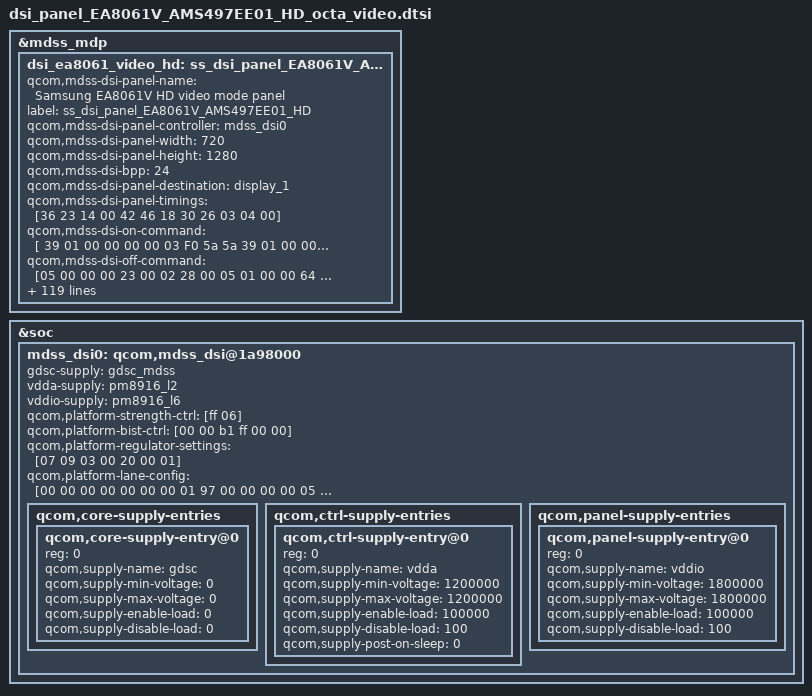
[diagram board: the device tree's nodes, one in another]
/* Copyright (c) 2013-2014, The Linux Foundation. All rights reserved.
 *
 * This program is free software; you can redistribute it and/or modify
 * it under the terms of the GNU General Public License version 2 and
 * only version 2 as published by the Free Software Foundation.
 *
 * This program is distributed in the hope that it will be useful,
 * but WITHOUT ANY WARRANTY; without even the implied warranty of
 * MERCHANTABILITY or FITNESS FOR A PARTICULAR PURPOSE.  See the
 * GNU General Public License for more details.
 */

/*---------------------------------------------------------------------------
 * This file is autogenerated file using gcdb parser. Please do not edit it.
 * Update input XML file to add a new entry or update variable in this file
 * VERSION = "1.0"
 *--------------------------------------------------------------------------- */
&mdss_mdp {
	dsi_ea8061_video_hd: ss_dsi_panel_EA8061V_AMS497EE01_HD {
		qcom,mdss-dsi-panel-name = "Samsung EA8061V HD video mode panel";
		label = "ss_dsi_panel_EA8061V_AMS497EE01_HD";
		qcom,mdss-dsi-panel-controller = <&mdss_dsi0>;
		qcom,mdss-dsi-panel-width = <720>;
		qcom,mdss-dsi-panel-height = <1280>;
		qcom,mdss-dsi-bpp = <24>;

		qcom,mdss-dsi-panel-destination = "display_1";
		qcom,mdss-dsi-panel-timings = [36 23 14 00 42 46 18 30 26 03 04 00];

		qcom,mdss-dsi-on-command = [
				39 01 00 00 00 00 03 F0 5a 5a
				39 01 00 00 00 00 03 F1 5a 5a

				/* common condition set */
				39 01 00 00 00 00 03 B8 19 10
				39 01 00 00 00 00 02 BA 57
				39 01 00 00 00 00 03 FC 5a 5a
				39 01 00 00 00 00 02 B0 0B
				39 01 00 00 00 00 03 D2 00 85
				39 01 00 00 00 00 02 CB 70
				39 01 00 00 00 00 03 FC a5 a5

				/* brightness control */
				39 01 00 00 00 00 22 CA
				    01 00 01 00 01 00
				    80 80 80 80 80 80
				    80 80 80 80 80 80
				    80 80 80 80 80 80
				    80 80 80 80 80 80
				    00 00 00
				39 01 00 00 00 00 05 B2 00 00 00 0a
				39 01 00 00 00 00 03 B6 5c 8a
				39 01 00 00 00 00 02 F7 01

				05 01 00 00 78 00 02 11 00
				39 01 00 00 00 00 03 F1 A5 A5
					];

		qcom,mdss-dsi-off-command = [05 00 00 00 23 00 02 28 00
				 05 01 00 00 64 00 02 10 00];

		qcom,mdss-dsi-panel-type = "dsi_video_mode";

		qcom,mdss-dsi-panel-framerate = <60>;
		qcom,mdss-dsi-virtual-channel-id = <0>;
		qcom,mdss-dsi-stream = <0>;
		qcom,cont-splash-enabled;
		qcom,mdss-dsi-force-clk-lane-hs;

		qcom,mdss-dsi-h-front-porch = <80>;
		qcom,mdss-dsi-h-back-porch = <128>;
		qcom,mdss-dsi-h-pulse-width = <96>;
		qcom,mdss-dsi-h-sync-skew = <0>;
		qcom,mdss-dsi-v-back-porch = <8>;
		qcom,mdss-dsi-v-front-porch = <14>;
		qcom,mdss-dsi-v-pulse-width = <2>;
		qcom,mdss-dsi-h-left-border = <0>;
		qcom,mdss-dsi-h-right-border = <0>;
		qcom,mdss-dsi-v-top-border = <0>;
		qcom,mdss-dsi-v-bottom-border = <0>;

		qcom,mdss-dsi-underflow-color = <0xff>;
		qcom,mdss-dsi-border-color = <0>;

		/* Dynamic FPS
		qcom,mdss-dsi-pan-enable-dynamic-fps= <1>;
		qcom,mdss-dsi-pan-fps-update = "dfps_immediate_porch_mode";*/


		qcom,mdss-dsi-gamma-update = [39 01 00 00 00 00 02 F7 01];
		qcom,mdss-dsi-on-command-state = "dsi_lp_mode";
		qcom,mdss-dsi-off-command-state = "dsi_hs_mode";
		qcom,mdss-dsi-h-sync-pulse = <0>;
		qcom,mdss-dsi-traffic-mode = "burst_mode";
		qcom,mdss-dsi-bllp-eof-power-mode;
		qcom,mdss-dsi-bllp-power-mode;
		qcom,mdss-dsi-lane-0-state;
		qcom,mdss-dsi-lane-1-state;
		qcom,mdss-dsi-lane-2-state;
		qcom,mdss-dsi-lane-3-state;

		qcom,mdss-dsi-t-clk-post = <0x04>;
		qcom,mdss-dsi-t-clk-pre = <0x1b>;
		qcom,mdss-dsi-bl-min-level = <1>;
		qcom,mdss-dsi-bl-max-level = <255>;
		qcom,mdss-dsi-dma-trigger = "trigger_sw";
		qcom,mdss-dsi-mdp-trigger = "none";

		qcom,mdss-dsi-bl-pmic-control-type = "bl_ctrl_dcs";
		qcom,mdss-dsi-reset-sequence = <1 20>, <0 1>, <1 20>;
		qcom,mdss-pan-physical-width-dimension = <62>;
		qcom,mdss-pan-physical-height-dimension = <110>;
		qcom,mdss-dsi-lp11-init;
		qcom,mdss-dsi-init-delay-us = <2000>;
		qcom,mdss-power-off-delay-us = <12000>;


/*
 * ************************************************************************************************************************************
 *
 *
 *			Below  parameters are samsung dependent thigs
 *
 *
 * ************************************************************************************************************************************
 */

		samsung,packet_size_tx_cmds_revA = [
			37 01 00 00 00 00 02 07 00
		];

		/*
		 * First parameters can be changed
		 * by function of samsung_nv_read()
		 * because of that means offset of
		 * read position
		 */
		samsung,reg_read_pos_tx_cmds_revA = [
			15 01 00 00 00 00 02 B0 00
		];

		samsung,display_on_tx_cmds_revA = [05 01 00 00 32 00 02 29 00];
		samsung,display_off_tx_cmds_revA = [05 01 00 00 32 00 02 28 00];

		samsung,level1_key_enable_tx_cmds_revA = [
			29 01 00 00 00 00 03 F0 5A 5A
		];
		samsung,level1_key_disable_tx_cmds_revA = [
			29 01 00 00 00 00 03 F0 A5 A5
		];
		samsung,level2_key_enable_tx_cmds_revA = [
			29 01 00 00 00 00 03 F0 5A 5A
			29 01 00 00 00 00 03 F1 5A 5A
			29 01 00 00 00 00 03 FC 5A 5A
		];
		samsung,level2_key_disable_tx_cmds_revA = [
			29 01 00 00 00 00 03 F0 A5 A5
			29 01 00 00 00 00 03 F1 A5 A5
			29 01 00 00 00 00 03 FC A5 A5
		];


		/*
		 * ************************************************************************************************************************
		 *	 06 01 00 00 00 00 01 c8 07 21
		 *	READ 0xC8 SIZE 0x07 OFFSET 0x21
		 * ************************************************************************************************************************
		 */
		samsung,smart_dimming_mtp_rx_cmds_revA = [ 06 01 00 00 00 00 01 c8 21 00];
		/* the last byte in all read commands will represent READ LENGH */
		samsung,manufacture_id0_rx_cmds_revA = [ 06 01 00 00 00 00 01 da 01 00];
		samsung,manufacture_id1_rx_cmds_revA = [ 06 01 00 00 00 00 01 db 01 00];
		samsung,manufacture_id2_rx_cmds_revA = [ 06 01 00 00 00 00 01 dc 01 00];

		samsung,manufacture_date_rx_cmds_revA = [ 06 01 00 00 00 00 01 c8 02 28];	/* read C8 41~42th , 40=0x28*/
		samsung,ddi_id_rx_cmds_revA = [ 06 01 00 00 00 00 01 d6 05 00];	/* read D6 1~5th */
		samsung,mtp_read_sysfs_rx_cmds_revA = [ 06 01 00 00 00 00 01 01 01 01];

		samsung,hbm_rx_cmds_revA = [ 06 01 00 00 00 00 01 c8 07 21];	/* read C8 34~40th , 33=0x21*/
		samsung,hbm2_rx_cmds_revA = [ 06 01 00 00 00 00 01 c8 0F 48];	/* read C8 73~87th , 72=0x48*/

		samsung,elvss_rx_cmds_revA = [ 06 01 00 00 00 00 01 b6 01 14];	/* read C6 21th , 20=0x14*/
		samsung,mdnie_read_rx_cmds_revA	= [ 06 01 00 00 00 00 01 A1 04 00];

		samsung,ldi_debug0_rx_cmds_revA = [06 01 00 00 00 00 01 0A 01 00];
		samsung,ldi_debug1_rx_cmds_revA = [06 01 00 00 00 00 01 0E 01 00];
		samsung,ldi_debug2_rx_cmds_revA = [06 01 00 00 00 00 01 EA 08 00];





		/*
		 * ************************************************************************************************************************
		 *	 COMMON CMD LIST
		 * ************************************************************************************************************************
		*/

		samsung,gamma_tx_cmds_revA = [
			29 01 00 00 00 00 22            /* Brightness Condition Set - Gamma 2.2 Setting*/
				CA 01 00 01 00 01 00 80
				80 80 80 80 80 80 80 80
				80 80 80 80 80 80 80 80
				80 80 80 80 80 80 80 00
				00 00
			29 01 00 00 00 00 02 F7 01	/* Gamma, LTPS(AID) update */
			];

		samsung,hbm_gamma_tx_cmds_revA = [
				29 01 00 00 00 00 22	/* Brightness Condition Set for HBM - Gamma 2.2 Setting*/
				CA 01 00 01 00 01 00 80
				80 80 80 80 80 80 80 80
				80 80 80 80 80 80 80 80
				80 80 80 80 80 80 80 00
				00 00
			];

		samsung,hbm_etc_tx_cmds_revA = [
			29 01 00 00 00 00 05 B2 00 0E 00 0E	/* AID 0% */
			29 01 00 00 00 00 16 B6
				88 04 00 00 00
				00 00 03 55 54
				20 00 0A AA AF
				0F 02 11 11 10
				00			/* HBM ELVSS Setting */
			/*29 01 00 00 00 00 07 B5 03 99 27 1F 45 0A*/	/* ACL control */
			29 01 00 00 00 00 02 55 02	/* RE(low) & ACL */
			29 01 00 00 00 00 02 B5 29	/* 32 frame Averaging (0x51) */
			29 01 00 00 00 00 02 00 00
			29 01 00 00 00 00 02 F7 01	/* Gamma, LTPS(AID) update */
			29 01 00 00 00 00 02 00 00
			29 01 00 00 00 00 02 F7 00
		];



		/*
		* ************************************************************************************************************************
		* AID command list and mappings
		* ************************************************************************************************************************
		*/

		samsung,aid_tx_cmds_revA = [
					39 00 00 00 00 00 05	B2 00 00 04 E4	/* 0 samsung_brightness_aor_95p7 */
					39 00 00 00 00 00 05	B2 00 00 04 DA	/* 1 samsung_brightness_aor_94p25 */
					39 00 00 00 00 00 05	B2 00 00 04 D0	/* 2 samsung_brightness_aor_93p33 */
					39 00 00 00 00 00 05	B2 00 00 04 C4	/* 3 samsung_brightness_aor_92p41 */
					39 00 00 00 00 00 05	B2 00 00 04 B8	/* 4 samsung_brightness_aor_91p41 */
					39 00 00 00 00 00 05	B2 00 00 04 AE	/* 5 samsung_brightness_aor_90p49 */
					39 00 00 00 00 00 05	B2 00 00 04 A4	/* 6 samsung_brightness_aor_89p65 */
					39 00 00 00 00 00 05	B2 00 00 04 98	/* 7 samsung_brightness_aor_88p73 */
					39 00 00 00 00 00 05	B2 00 00 04 8C	/* 8 samsung_brightness_aor_87p88 */
					39 00 00 00 00 00 05	B2 00 00 04 80	/* 9 samsung_brightness_aor_87p04 */
					39 00 00 00 00 00 05	B2 00 00 04 74	/* 10 samsung_brightness_aor_85p89 */
					39 00 00 00 00 00 05	B2 00 00 04 68	/* 11 samsung_brightness_aor_84p97 */
					39 00 00 00 00 00 05	B2 00 00 04 5C	/* 12 samsung_brightness_aor_84p05 */
					39 00 00 00 00 00 05	B2 00 00 04 44	/* 13 samsung_brightness_aor_82p21 */
					39 00 00 00 00 00 05	B2 00 00 04 38	/* 14 samsung_brightness_aor_81p21 */
					39 00 00 00 00 00 05	B2 00 00 04 25	/* 15 samsung_brightness_aor_80p83 */
					39 00 00 00 00 00 05	B2 00 00 04 18	/* 16 samsung_brightness_aor_80p29 */
					39 00 00 00 00 00 05	B2 00 00 04 01	/* 17 samsung_brightness_aor_77p61 */
					39 00 00 00 00 00 05	B2 00 00 03 F5	/* 18 samsung_brightness_aor_76p69 */
					39 00 00 00 00 00 05	B2 00 00 03 DB	/* 19 samsung_brightness_aor_74p92 */
					39 00 00 00 00 00 05	B2 00 00 03 C5	/* 20 samsung_brightness_aor_73p08 */
					39 00 00 00 00 00 05	B2 00 00 03 B7	/* 21 samsung_brightness_aor_72p09 */
					39 00 00 00 00 00 05	B2 00 00 03 9E	/* 22 samsung_brightness_aor_70p17 */
					39 00 00 00 00 00 05	B2 00 00 03 88	/* 23 samsung_brightness_aor_68p25 */
					39 00 00 00 00 00 05	B2 00 00 03 64	/* 24 samsung_brightness_aor_65p41 */
					39 00 00 00 00 00 05	B2 00 00 03 4B	/* 25 samsung_brightness_aor_63p50 */
					39 00 00 00 00 00 05	B2 00 00 03 32	/* 26 samsung_brightness_aor_61p58 */
					39 00 00 00 00 00 05	B2 00 00 03 0D	/* 27 samsung_brightness_aor_58p82 */
					39 00 00 00 00 00 05	B2 00 00 02 E7	/* 28 samsung_brightness_aor_53p22 */
					39 00 00 00 00 00 05	B2 00 00 02 C2	/* 29 samsung_brightness_aor_50p38 */
					39 00 00 00 00 00 05	B2 00 00 02 9D	/* 30 samsung_brightness_aor_47p62 */
					39 00 00 00 00 00 05	B2 00 00 02 79	/* 31 samsung_brightness_aor_43p87 */
					39 00 00 00 00 00 05	B2 00 00 02 45	/* 32 samsung_brightness_aor_40p11 */
					39 00 00 00 00 00 05	B2 00 00 02 13	/* 33 samsung_brightness_aor_39p95 */
					39 00 00 00 00 00 05	B2 00 00 01 E7	/* 34 samsung_brightness_aor_37p35 */
					39 00 00 00 00 00 05	B2 00 00 01 AE	/* 35 samsung_brightness_aor_32p29 */
					39 00 00 00 00 00 05	B2 00 00 01 76	/* 36 samsung_brightness_aor_27p99 */
					39 00 00 00 00 00 05	B2 00 00 01 39	/* 37 samsung_brightness_aor_22p70 */
					39 00 00 00 00 00 05	B2 00 00 00 F8	/* 38 samsung_brightness_aor_17p33 */
					39 00 00 00 00 00 05	B2 00 00 00 B4	/* 39 samsung_brightness_aor_11p66 */
					39 00 00 00 00 00 05	B2 00 00 00 63	/* 40 samsung_brightness_aor_11p66 */
					39 00 00 00 00 00 05	B2 00 00 00 0A	/* 41 samsung_brightness_aor_5p37 */
			];


		samsung,aid_map_table_revA = <
				5	0		6	1		7	2		8	3		9	4
				10	5		11	6		12	7		13	8		14	9
				15	10		16	11		17	12		19	13		20	14
				21	15		22	16		24	17		25	18		27	19
				29	20		30	21		32	22		34	23		37	24
				39	25		41	26		44	27		47	28		50	29
				53	30		56	31		60	32		64	33		68	34
				72	34		77	34		82	34		87	34		93	34
				98	34		105	34		111	34		119	34		126	34
				134	34		143	34		152	34		162	34		172	35
				183	36		195	37		207	38		220	39		234	40
				249	41		265	41		282	41		300	41		316	41
				333	41		350	41		360	41
		>;

		/*
		* ************************************************************************************************************************
		* ACL command list and mappings
		* ************************************************************************************************************************
		*/
		samsung,acl_on_tx_cmds_revA = [
			29 01 00 00 00 00 02 B5 29	/* ACL ON - 50 (32Frame Averaging) */			
			29 01 00 00 00 00 02 55 02	/* ACL 15%(default) */
/*			29 01 00 00 00 00 02 F7 01*/
		];

		samsung,acl_off_tx_cmds_revA = [
			29 01 00 00 00 00 02 B5 21	/* ACL ON - 50 (32Frame Averaging) */
			29 01 00 00 00 00 02 55 00	/* ACL 15%(default) */
/*			29 01 00 00 00 00 02 F7 01*/
		];

		samsung,acl_percent_tx_cmds_revA = [
			29 01 00 00 00 00 02 55 00
			29 01 00 00 00 00 02 55 01	/* ACL 25% */
			29 01 00 00 00 00 02 55 02	/* default ACL 15% */
			29 01 00 00 00 00 02 55 40	/* ACL 50% */

		];



		samsung,acl_map_table_revA =  <
					5    2	6    2	7    2	8    2	9    2
					10   2	11   2	12   2	13   2	14   2
					15   2	16   2	17   2	19   2	20   2
					21   2	22   2	24   2	25   2	27   2
					29   2	30   2	32   2	34   2	37   2
					39   2	41   2	44   2	47   2	50   2
					53   2	56   2	60   2	64   2	68   2
					72   2	77   2	82   2	87   2	93   2
					98   2	105  2	111  2	119  2	126  2
					134  2	143  2	152  2	162  2	172  2
					183  2	195  2	207  2	220  2	234  2
					249  2	265  2	282  2	300  2	316  2
					333  2	350  2	360  2
		>;

		/*
		 * ************************************************************************************************************************
		 * ELVSS(ACL Off) command list and mappings
		 * ************************************************************************************************************************
		 */
		samsung,elvss_tx_cmds_revA = [
					39 00 00 00 00 00 03 b6 4c 8A /* 0    5~7 nit : 0x8A */
					39 00 00 00 00 00 03 b6 4c 8B /* 1    8 nit  : 0x8B */
					39 00 00 00 00 00 03 b6 4c 8C /* 2    9 nit  : 0x8C */
					39 00 00 00 00 00 03 b6 4c 8D /* 3    10 nit : 0x8D */
					39 00 00 00 00 00 03 b6 4c 8E /* 4    11 nit : 0x8E */
					39 00 00 00 00 00 03 b6 4c 8F /* 5    12 nit : 0x8F */
					39 00 00 00 00 00 03 b6 4c 90 /* 6    13 nit : 0x90 */
					39 00 00 00 00 00 03 b6 4c 91 /* 7    14 nit : 0x91 */
					39 00 00 00 00 00 03 b6 4c 92 /* 8    15 nit : 0x92 */
					39 00 00 00 00 00 03 b6 4c 93 /* 9    16 nit : 0x93 */
					39 00 00 00 00 00 03 b6 4c 94 /* 10   17 nit : 0x94 */
					39 00 00 00 00 00 03 b6 4c 95 /* 11   19 nit : 0x95 */
					39 00 00 00 00 00 03 b6 5c 96 /* 12   20 nit : 0x96 */
					39 00 00 00 00 00 03 b6 5c 9B /* 13   82 ~ 21 nit : 0x9B */
					39 00 00 00 00 00 03 b6 5c 9A /* 14   93 ~ 87 nit : 0x9A */
					39 00 00 00 00 00 03 b6 5c 99 /* 15   105 ~ 98 nit : 0x99 */
					39 00 00 00 00 00 03 b6 5c 98 /* 16   111 nit : 0x98 */
					39 00 00 00 00 00 03 b6 5c 97 /* 17   126 ~ 119 nit : 0x97 */
					39 00 00 00 00 00 03 b6 5c 96 /* 18   134 nit : 0x96 */
					39 00 00 00 00 00 03 b6 5c 95 /* 19   143 nit : 0x95 */
					39 00 00 00 00 00 03 b6 5c 94 /* 20   172 ~ 152 nit : 0x94 */
					39 00 00 00 00 00 03 b6 5c 93 /* 21   183 nit : 0x93 */
					39 00 00 00 00 00 03 b6 5c 92 /* 22   195 nit : 0x92 */
					39 00 00 00 00 00 03 b6 5c 91 /* 23   207 nit : 0x91 */
					39 00 00 00 00 00 03 b6 5c 90 /* 24   249 ~ 220 nit : 0x90 */
					39 00 00 00 00 00 03 b6 5c 8F /* 25   265 nit : 0x8F */
					39 00 00 00 00 00 03 b6 5c 8E /* 26   282 nit : 0x8E */
					39 00 00 00 00 00 03 b6 5c 8D /* 27   300 nit : 0x8D */
					39 00 00 00 00 00 03 b6 5c 8C /* 28   316 nit : 0x8C */
					39 00 00 00 00 00 03 b6 5c 8B /* 29   333 nit : 0x8B */
					39 00 00 00 00 00 03 b6 5c 8A /* 30   350 nit : 0x8A */
		];

		/*
		* ************************************************************************************************************************
		 * SMART ACL(ACL On) ELVSS command list and mappings
		* ************************************************************************************************************************
		*/
		samsung,smart_acl_elvss_tx_cmds_revA = [
					39 00 00 00 00 00 03 b6 4c 8A /* 0    5~7 nit : 0x8A */
					39 00 00 00 00 00 03 b6 4c 8B /* 1    8 nit : 0x8B */
					39 00 00 00 00 00 03 b6 4c 8C /* 2    9 nit : 0x8C */
					39 00 00 00 00 00 03 b6 4c 8D /* 3    10 nit : 0x8D */
					39 00 00 00 00 00 03 b6 4c 8E /* 4    11 nit : 0x8E */
					39 00 00 00 00 00 03 b6 4c 8F /* 5    12 nit : 0x8F */
					39 00 00 00 00 00 03 b6 4c 90 /* 6    13 nit : 0x90 */
					39 00 00 00 00 00 03 b6 4c 91 /* 7    14 nit : 0x91 */
					39 00 00 00 00 00 03 b6 4c 92 /* 8    15 nit : 0x92 */
					39 00 00 00 00 00 03 b6 4c 93 /* 9    16 nit : 0x93 */
					39 00 00 00 00 00 03 b6 4c 94 /* 10   17 nit : 0x94 */
					39 00 00 00 00 00 03 b6 4c 95 /* 11   19 nit : 0x95 */
					39 00 00 00 00 00 03 b6 4c 96 /* 12   20 nit : 0x96 */
					39 00 00 00 00 00 03 b6 4c 9B /* 13   82 ~ 21 nit : 0x9B */
					39 00 00 00 00 00 03 b6 4c 9A /* 14   93 ~ 87 nit : 0x9A */
					39 00 00 00 00 00 03 b6 4c 99 /* 15   105 ~ 98 nit : 0x99 */
					39 00 00 00 00 00 03 b6 4c 98 /* 16   111 nit : 0x98 */
					39 00 00 00 00 00 03 b6 4c 97 /* 17   126 ~ 119 nit : 0x97 */
					39 00 00 00 00 00 03 b6 4c 96 /* 18   134 nit : 0x96 */
					39 00 00 00 00 00 03 b6 4c 95 /* 19   143 nit : 0x95 */
					39 00 00 00 00 00 03 b6 4c 94 /* 20   172 ~ 152 nit : 0x94 */
					39 00 00 00 00 00 03 b6 4c 93 /* 21   183 nit : 0x93 */
					39 00 00 00 00 00 03 b6 4c 92 /* 22   195 nit : 0x92 */
					39 00 00 00 00 00 03 b6 4c 91 /* 23   207 nit : 0x91 */
					39 00 00 00 00 00 03 b6 4c 90 /* 24   249 ~ 220 nit : 0x90 */
					39 00 00 00 00 00 03 b6 4c 8F /* 25   265 nit : 0x8F */
					39 00 00 00 00 00 03 b6 4c 8E /* 26   282 nit : 0x8E */
					39 00 00 00 00 00 03 b6 4c 8D /* 27   300 nit : 0x8D */
					39 00 00 00 00 00 03 b6 4c 8C /* 28   316 nit : 0x8C */
					39 00 00 00 00 00 03 b6 4c 8B /* 29   333 nit : 0x8B */
					39 00 00 00 00 00 03 b6 4c 8A /* 30   350 nit : 0x8A */
		];


		samsung,elvss_lowtemp_tx_cmds_revA = [
			29 01 00 00 00 00 02 B8 00			
		];	/* Low Temperature Command */

		samsung,elvss_lowtemp2_tx_cmds_revA = [
			29 01 00 00 00 00 02 B8 00						
		];	/* Low Temperature Command: default */


		/* bl_level, Index in elvss command list */
		samsung,smart_acl_elvss_map_table_revA = <
					5	0		6	0		7	0		8	1		9	2
					10	3		11	4		12	5		13	6		14	7
					15	8		16	9		17	10		19	11		20	12
					21	13		22	13		24	13		25	13		27	13
					29	13		30	13		32	13		34	13		37	13
					39	13		41	13		44	13		47	13		50	13
					53	13		56	13		60	13		64	13		68	13
					72	13		77	13		82	13		87	14		93	14
					98	15		105	15		111	16		119	17		126	17
					134	18		143	19		152	20		162	20		172	20
					183	21		195	22		207	23		220	24		234	24
					249	24		265	25		282	26		300	27		316	28
					333	29		350	30		360	30
			>;


		/*
		* ************************************************************************************************************************
		* candela to index mappings
		* ************************************************************************************************************************
		*/
		samsung,candela_map_table_revA = <
		/*<idx>	  <from>  <till> <candella> */
				0		0		5		5
				1		6		6		6
				2		7		7		7
				3		8		8		8
				4		9		9		9
				5		10		10		10
				6		11		11		11
				7		12		12		12
				8		13		13		13
				9		14		14		14
				10		15		15		15
				11		16		16		16
				12		17		17		17
				13		18		18		19
				14		19		19		20
				15		20		20		21
				16		21		21		22
				17		22		22		24
				18		23		23		25
				19		24		24		27
				20		25		25		29
				21		26		26		30
				22		27		27		32
				23		28		28		34
				24		29		29		37
				25		30		30		39
				26		31		32		41
				27		33		34		44
				28		35		36		47
				29		37		38		50
				30		39		40		53
				31		41		43		56
				32		44		45		60
				33		46		48		64
				34		49		51		68
				35		52		55		72
				36		56		59		77
				37		60		63		82
				38		64		67		87
				39		68		71		93
				40		71		74		98
				41		75		79		105
				42		80		85		111
				43		86		91		119
				44		92		97		126
				45		97		103	134
				46		104		110		143
				47		111		117		152
				48		118		125		162
				49		126		133		172
				50		134		142		183
				51		143		151		195
				52		152		161		207
				53		162		171		220
				54		172		182		234
				55		183		194		249
				56		195		206		265
				57		207		218		282
				58		219		230		300
				59		231		242		316
				60		243		253		333
				61		254		255		360
		>;


	
	};
};
&soc {
	mdss_dsi0: qcom,mdss_dsi@1a98000 {
		gdsc-supply = <&gdsc_mdss>;
		vdda-supply = <&pm8916_l2>;
		vddio-supply = <&pm8916_l6>;
		qcom,platform-strength-ctrl = [ff 06];
		qcom,platform-bist-ctrl = [00 00 b1 ff 00 00];
		qcom,platform-regulator-settings = [07 09 03 00 20 00 01];
		qcom,platform-lane-config = [00 00 00 00 00 00 00 01 97
			00 00 00 00 05 00 00 01 97
			00 00 00 00 0a 00 00 01 97
			00 00 00 00 0f 00 00 01 97
			00 c0 00 00 00 00 00 01 bb];
		qcom,core-supply-entries {
			#address-cells = <1>;
			#size-cells = <0>;

			qcom,core-supply-entry@0 {
				reg = <0>;
				qcom,supply-name = "gdsc";
				qcom,supply-min-voltage = <0>;
				qcom,supply-max-voltage = <0>;
				qcom,supply-enable-load = <0>;
				qcom,supply-disable-load = <0>;
			};
		};
		qcom,ctrl-supply-entries {
			#address-cells = <1>;
			#size-cells = <0>;

			qcom,ctrl-supply-entry@0 {
				reg = <0>;
				qcom,supply-name = "vdda";
				qcom,supply-min-voltage = <1200000>;
				qcom,supply-max-voltage = <1200000>;
				qcom,supply-enable-load = <100000>;
				qcom,supply-disable-load = <100>;
				qcom,supply-post-on-sleep = <0>;
			};
		};
		qcom,panel-supply-entries {
			#address-cells = <1>;
			#size-cells = <0>;

			qcom,panel-supply-entry@0 {
				reg = <0>;
				qcom,supply-name = "vddio";
				qcom,supply-min-voltage = <1800000>;
				qcom,supply-max-voltage = <1800000>;
				qcom,supply-enable-load = <100000>;
				qcom,supply-disable-load = <100>;
			};
		};
	};
};
